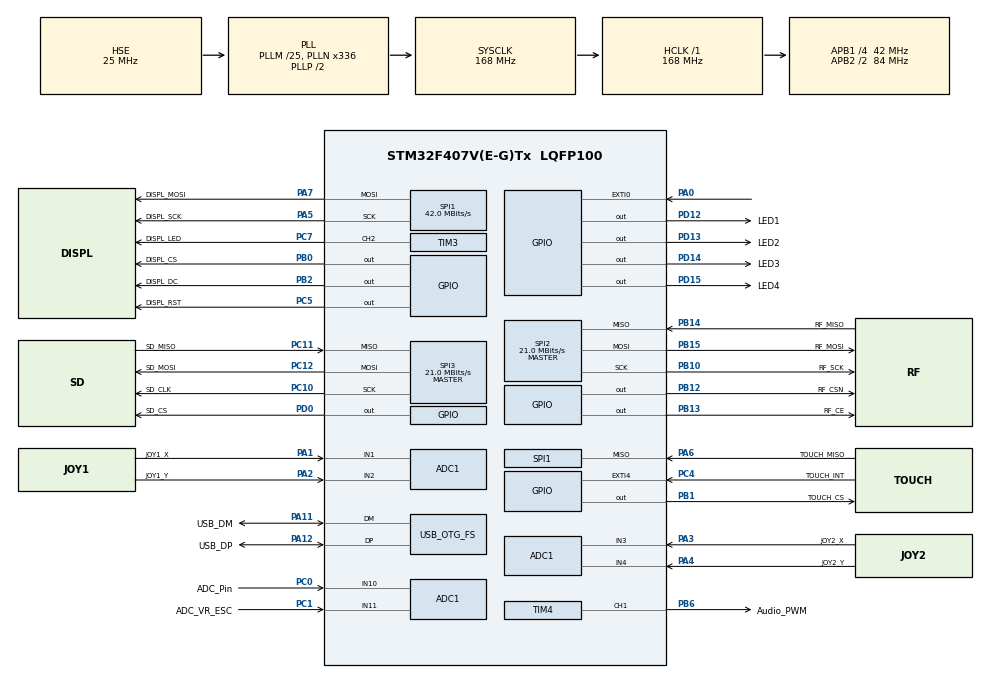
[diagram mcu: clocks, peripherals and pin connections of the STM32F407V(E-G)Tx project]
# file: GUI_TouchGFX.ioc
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ADC1.Channel-0\#ChannelRegularConversion=ADC_CHANNEL_1
ADC1.Channel-1\#ChannelRegularConversion=ADC_CHANNEL_2
ADC1.Channel-2\#ChannelRegularConversion=ADC_CHANNEL_3
ADC1.Channel-3\#ChannelRegularConversion=ADC_CHANNEL_4
ADC1.Channel-4\#ChannelRegularConversion=ADC_CHANNEL_10
ADC1.ClockPrescaler=ADC_CLOCK_SYNC_PCLK_DIV8
ADC1.ContinuousConvMode=DISABLE
ADC1.DiscontinuousConvMode=DISABLE
ADC1.EOCSelection=ADC_EOC_SINGLE_CONV
ADC1.NbrOfConversion=5
ADC1.NbrOfConversionFlag=1
ADC1.Rank-0\#ChannelRegularConversion=1
ADC1.Rank-1\#ChannelRegularConversion=2
ADC1.Rank-2\#ChannelRegularConversion=3
ADC1.Rank-3\#ChannelRegularConversion=4
ADC1.Rank-4\#ChannelRegularConversion=5
ADC1.SamplingTime-0\#ChannelRegularConversion=ADC_SAMPLETIME_144CYCLES
ADC1.SamplingTime-1\#ChannelRegularConversion=ADC_SAMPLETIME_144CYCLES
ADC1.SamplingTime-2\#ChannelRegularConversion=ADC_SAMPLETIME_144CYCLES
ADC1.SamplingTime-3\#ChannelRegularConversion=ADC_SAMPLETIME_144CYCLES
ADC1.SamplingTime-4\#ChannelRegularConversion=ADC_SAMPLETIME_144CYCLES
ADC1.ScanConvMode=ENABLE
ADC1.master=1
Dma.ADC1.1.Direction=DMA_PERIPH_TO_MEMORY
Dma.ADC1.1.FIFOMode=DMA_FIFOMODE_DISABLE
Dma.ADC1.1.Instance=DMA2_Stream0
Dma.ADC1.1.MemDataAlignment=DMA_MDATAALIGN_WORD
Dma.ADC1.1.MemInc=DMA_MINC_ENABLE
Dma.ADC1.1.Mode=DMA_CIRCULAR
Dma.ADC1.1.PeriphDataAlignment=DMA_PDATAALIGN_WORD
Dma.ADC1.1.PeriphInc=DMA_PINC_DISABLE
Dma.ADC1.1.Priority=DMA_PRIORITY_VERY_HIGH
Dma.Request0=SPI1_TX
Dma.Request1=ADC1
Dma.SPI1_TX.0.Direction=DMA_MEMORY_TO_PERIPH
Dma.SPI1_TX.0.FIFOMode=DMA_FIFOMODE_DISABLE
Dma.SPI1_TX.0.Instance=DMA2_Stream3
Dma.SPI1_TX.0.MemDataAlignment=DMA_MDATAALIGN_BYTE
Dma.SPI1_TX.0.MemInc=DMA_MINC_ENABLE
Dma.SPI1_TX.0.Mode=DMA_NORMAL
Dma.SPI1_TX.0.PeriphDataAlignment=DMA_PDATAALIGN_BYTE
Dma.SPI1_TX.0.PeriphInc=DMA_PINC_DISABLE
Dma.SPI1_TX.0.Priority=DMA_PRIORITY_VERY_HIGH
Mcu.Family=STM32F4
Mcu.Name=STM32F407V(E-G)Tx
Mcu.Package=LQFP100
NVIC.DMA2_Stream0_IRQn=true\:0\:0\:false\:false\:true\:false\:true\:true
NVIC.DMA2_Stream3_IRQn=true\:0\:0\:false\:false\:true\:false\:true\:true
NVIC.EXTI4_IRQn=true\:0\:0\:true\:false\:true\:true\:true\:true
NVIC.PriorityGroup=NVIC_PRIORITYGROUP_4
NVIC.SPI1_IRQn=true\:0\:0\:false\:false\:true\:true\:true\:true
PA0-WKUP.Signal=GPXTI0
PA1.GPIO_Label=JOY1_X
PA1.Signal=ADCx_IN1
PA11.GPIO_Label=USB_DM
PA11.Mode=Device_Only
PA11.Signal=USB_OTG_FS_DM
PA12.GPIO_Label=USB_DP
PA12.Mode=Device_Only
PA12.Signal=USB_OTG_FS_DP
PA13.Mode=Serial_Wire
PA13.Signal=SYS_JTMS-SWDIO
PA14.Mode=Serial_Wire
PA14.Signal=SYS_JTCK-SWCLK
PA2.GPIO_Label=JOY1_Y
PA2.Signal=ADCx_IN2
PA3.GPIO_Label=JOY2_X
PA3.Signal=ADCx_IN3
PA4.GPIO_Label=JOY2_Y
PA4.Signal=ADCx_IN4
PA5.GPIO_Label=DISPL_SCK
PA5.Mode=Full_Duplex_Master
PA5.Signal=SPI1_SCK
PA6.GPIO_Label=TOUCH_MISO
PA6.Mode=Full_Duplex_Master
PA6.Signal=SPI1_MISO
PA7.GPIO_Label=DISPL_MOSI
PA7.Mode=Full_Duplex_Master
PA7.Signal=SPI1_MOSI
PB0.GPIO_Label=DISPL_CS
PB0.GPIO_PuPd=GPIO_NOPULL
PB0.GPIO_Speed=GPIO_SPEED_FREQ_HIGH
PB0.PinState=GPIO_PIN_SET
PB0.Signal=GPIO_Output
PB1.GPIO_Label=TOUCH_CS
PB1.GPIO_Speed=GPIO_SPEED_FREQ_HIGH
PB1.PinState=GPIO_PIN_SET
PB1.Signal=GPIO_Output
PB10.GPIO_Label=RF_SCK
PB10.Mode=Full_Duplex_Master
PB10.Signal=SPI2_SCK
PB12.GPIO_Label=RF_CSN
PB12.Signal=GPIO_Output
PB13.GPIO_Label=RF_CE
PB13.Signal=GPIO_Output
PB14.GPIO_Label=RF_MISO
PB14.Mode=Full_Duplex_Master
PB14.Signal=SPI2_MISO
PB15.GPIO_Label=RF_MOSI
PB15.Mode=Full_Duplex_Master
PB15.Signal=SPI2_MOSI
PB2.GPIO_Label=DISPL_DC
PB2.GPIO_Speed=GPIO_SPEED_FREQ_HIGH
PB2.Signal=GPIO_Output
PB6.GPIO_Label=Audio_PWM
PB6.Signal=S_TIM4_CH1
PC0.GPIO_Label=ADC_Pin
PC0.Signal=ADCx_IN10
PC1.GPIO_Label=ADC_VR_ESC
PC1.Signal=ADCx_IN11
PC10.GPIO_Label=SD_CLK
PC10.Mode=Full_Duplex_Master
PC10.Signal=SPI3_SCK
PC11.GPIO_Label=SD_MISO
PC11.Mode=Full_Duplex_Master
PC11.Signal=SPI3_MISO
PC12.GPIO_Label=SD_MOSI
PC12.Mode=Full_Duplex_Master
PC12.Signal=SPI3_MOSI
PC4.GPIO_Label=TOUCH_INT
PC4.GPIO_ModeDefaultEXTI=GPIO_MODE_IT_FALLING
PC4.GPIO_PuPd=GPIO_PULLUP
PC4.Signal=GPXTI4
PC5.GPIO_Label=DISPL_RST
PC5.Signal=GPIO_Output
PC7.GPIO_Label=DISPL_LED
PC7.Signal=S_TIM3_CH2
PD0.GPIO_Label=SD_CS
PD0.Signal=GPIO_Output
PD12.GPIO_Label=LED1
PD12.Signal=GPIO_Output
PD13.GPIO_Label=LED2
PD13.Signal=GPIO_Output
PD14.GPIO_Label=LED3
PD14.Signal=GPIO_Output
PD15.GPIO_Label=LED4
PD15.Signal=GPIO_Output
PH0-OSC_IN.Mode=HSE-External-Oscillator
PH0-OSC_IN.Signal=RCC_OSC_IN
PH1-OSC_OUT.Mode=HSE-External-Oscillator
PH1-OSC_OUT.Signal=RCC_OSC_OUT
ProjectManager.HeapSize=0x200
ProjectManager.StackSize=0x400
ProjectManager.TargetToolchain=STM32CubeIDE
RCC.48MHZClocksFreq_Value=48000000
RCC.AHBFreq_Value=168000000
RCC.APB1CLKDivider=RCC_HCLK_DIV4
RCC.APB1Freq_Value=42000000
RCC.APB1TimFreq_Value=84000000
RCC.APB2CLKDivider=RCC_HCLK_DIV2
RCC.APB2Freq_Value=84000000
RCC.APB2TimFreq_Value=168000000
RCC.CortexFreq_Value=168000000
RCC.HCLKFreq_Value=168000000
RCC.HSE_VALUE=25000000
RCC.HSI_VALUE=16000000
RCC.LSE_VALUE=32768
RCC.PLLM=25
RCC.PLLN=336
RCC.PLLQ=7
RCC.SYSCLKFreq_VALUE=168000000
RCC.SYSCLKSource=RCC_SYSCLKSOURCE_PLLCLK
RCC.VCOOutputFreq_Value=336000000
SH.ADCx_IN1.0=ADC1_IN1,IN1
SH.ADCx_IN10.0=ADC1_IN10,IN10
SH.ADCx_IN11.0=ADC1_IN11,IN11
SH.ADCx_IN2.0=ADC1_IN2,IN2
SH.ADCx_IN3.0=ADC1_IN3,IN3
SH.ADCx_IN4.0=ADC1_IN4,IN4
SH.S_TIM3_CH2.0=TIM3_CH2,PWM Generation2 CH2
SH.S_TIM4_CH1.0=TIM4_CH1,PWM Generation1 CH1
SPI1.CalculateBaudRate=42.0 MBits/s
SPI1.Direction=SPI_DIRECTION_2LINES
SPI1.Mode=SPI_MODE_MASTER
SPI1.VirtualType=VM_MASTER
SPI2.CalculateBaudRate=21.0 MBits/s
SPI2.Direction=SPI_DIRECTION_2LINES
SPI2.Mode=SPI_MODE_MASTER
SPI2.VirtualType=VM_MASTER
SPI3.CalculateBaudRate=21.0 MBits/s
SPI3.Direction=SPI_DIRECTION_2LINES
SPI3.Mode=SPI_MODE_MASTER
SPI3.VirtualType=VM_MASTER
STMicroelectronics.X-CUBE-TOUCHGFX.4.23.2.ApplicationCcGraphicsJjApplication=TouchGFXOoGenerator
STMicroelectronics.X-CUBE-TOUCHGFX.4.23.2.tgfx_block_size=2800
STMicroelectronics.X-CUBE-TOUCHGFX.4.23.2.tgfx_buffering_strategy=Partial
STMicroelectronics.X-CUBE-TOUCHGFX.4.23.2.tgfx_custom_height=240
STMicroelectronics.X-CUBE-TOUCHGFX.4.23.2.tgfx_custom_width=320
STMicroelectronics.X-CUBE-TOUCHGFX.4.23.2_IsPackSelfContextualization=true
TIM2.Period=50
TIM2.Prescaler=42000
TIM3.Channel-PWM\ Generation2\ CH2=TIM_CHANNEL_2
TIM3.Period=100
TIM3.Prescaler=10000
TIM4.Channel-PWM\ Generation1\ CH1=TIM_CHANNEL_1
USB_OTG_FS.VirtualMode=Device_Only
VP_CRC_VS_CRC.Mode=CRC_Activate
VP_STMicroelectronics.X-CUBE-TOUCHGFX_VS_GraphicsJjApplication_4.23.2.Mode=GraphicsJjApplication
VP_TIM2_VS_ClockSourceINT.Mode=Internal
board=custom

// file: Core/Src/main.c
/* USER CODE BEGIN Header */
/**
  ******************************************************************************
  * @file           : main.c
  * @brief          : Main program body
  ******************************************************************************
  * @attention
  *
  * Copyright (c) 2024 STMicroelectronics.
  * All rights reserved.
  *
  * This software is licensed under terms that can be found in the LICENSE file
  * in the root directory of this software component.
  * If no LICENSE file comes with this software, it is provided AS-IS.
  *
  ******************************************************************************
  */
/* USER CODE END Header */
#include "main.h"
#include "app_touchgfx.h"

/* USER CODE BEGIN Includes */
#include <stdbool.h>
/* USER CODE END Includes */

ADC_HandleTypeDef hadc1;
DMA_HandleTypeDef hdma_adc1;

CRC_HandleTypeDef hcrc;

SPI_HandleTypeDef hspi1;
SPI_HandleTypeDef hspi2;
SPI_HandleTypeDef hspi3;
DMA_HandleTypeDef hdma_spi1_tx;

TIM_HandleTypeDef htim2;
TIM_HandleTypeDef htim3;
TIM_HandleTypeDef htim4;

PCD_HandleTypeDef hpcd_USB_OTG_FS;

/* USER CODE BEGIN PV */
uint8_t TxAddress[] = {0x17, 0x08, 0x04, 0x11, 0x02};
uint8_t TxData[3] ={0};
uint8_t a = 0;
uint32_t VR[5];
uint32_t value[5];
uint32_t check;
uint8_t Temp[2]= {0};
/* USER CODE END PV */

void SystemClock_Config(void);
static void MX_GPIO_Init(void);
static void MX_DMA_Init(void);
static void MX_SPI1_Init(void);
static void MX_CRC_Init(void);
static void MX_TIM3_Init(void);
static void MX_SPI2_Init(void);
static void MX_TIM2_Init(void);
static void MX_ADC1_Init(void);
static void MX_SPI3_Init(void);
static void MX_TIM4_Init(void);
static void MX_USB_OTG_FS_PCD_Init(void);

/* USER CODE BEGIN 0 */
long map(long x, long in_min, long in_max, long out_min, long out_max)
{
  return (x - in_min) * (out_max - out_min + 1) / (in_max - in_min + 1) + out_min;
}
/* USER CODE END 0 */

int main(void)
{

  /* MCU Configuration--------------------------------------------------------*/

  /* Reset of all peripherals, Initializes the Flash interface and the Systick. */
  HAL_Init();

  /* Configure the system clock */
  SystemClock_Config();

  /* Initialize all configured peripherals */
  MX_GPIO_Init();
  MX_DMA_Init();
  MX_SPI1_Init();
  MX_CRC_Init();
  MX_TIM3_Init();
  MX_SPI2_Init();
  MX_TIM2_Init();
  MX_ADC1_Init();
  MX_SPI3_Init();
  MX_TIM4_Init();
  MX_USB_OTG_FS_PCD_Init();
  MX_TouchGFX_Init();
  /* USER CODE BEGIN 2 */
//  Displ_Init(Displ_Orientat_90);		// initialize the display and set the initial display orientation (here is orientaton: 0°) - THIS FUNCTION MUST PRECEED ANY OTHER DISPLAY FUNCTION CALL.
//  touchgfxSignalVSync();		// asks TouchGFX to start initial display drawing
//  Displ_BackLight('I');
  /* USER CODE END 2 */

  /* Infinite loop */
  /* USER CODE BEGIN WHILE */
  while (1)
  {
	  HAL_ADC_Start_DMA(&hadc1, VR, 5);
	  HAL_Delay(10);
//	  for(uint8_t i = 0; i < 5; i++){
//		  value[i] = map(VR[i], 0 , 4095, 0 ,1024);
//	  }
//	  check = value[3];
//	  if(check > 512){
//		HAL_GPIO_WritePin(GPIOD, GPIO_PIN_12, 1);
//	  }
//	  else HAL_GPIO_WritePin(GPIOD, GPIO_PIN_12, 0);
//	  IntToStr6(Temp[0],TxData);
//	  if (Touch_GotATouch(0))
//	  	touchgfxSignalVSync();		// asks TouchGFX to handle touch and redraw screen
    /* USER CODE END WHILE */

  MX_TouchGFX_Process();
  }
}

void SystemClock_Config(void)
{
  RCC_OscInitTypeDef RCC_OscInitStruct = {0};
  RCC_ClkInitTypeDef RCC_ClkInitStruct = {0};

  /** Configure the main internal regulator output voltage
  */
  __HAL_RCC_PWR_CLK_ENABLE();
  __HAL_PWR_VOLTAGESCALING_CONFIG(PWR_REGULATOR_VOLTAGE_SCALE1);

  /** Initializes the RCC Oscillators according to the specified parameters
  * in the RCC_OscInitTypeDef structure.
  */
  RCC_OscInitStruct.OscillatorType = RCC_OSCILLATORTYPE_HSE;
  RCC_OscInitStruct.HSEState = RCC_HSE_ON;
  RCC_OscInitStruct.PLL.PLLState = RCC_PLL_ON;
  RCC_OscInitStruct.PLL.PLLSource = RCC_PLLSOURCE_HSE;
  RCC_OscInitStruct.PLL.PLLM = 25;
  RCC_OscInitStruct.PLL.PLLN = 336;
  RCC_OscInitStruct.PLL.PLLP = RCC_PLLP_DIV2;
  RCC_OscInitStruct.PLL.PLLQ = 7;
  if (HAL_RCC_OscConfig(&RCC_OscInitStruct) != HAL_OK)
  {
    Error_Handler();
  }

  /** Initializes the CPU, AHB and APB buses clocks
  */
  RCC_ClkInitStruct.ClockType = RCC_CLOCKTYPE_HCLK|RCC_CLOCKTYPE_SYSCLK
                              |RCC_CLOCKTYPE_PCLK1|RCC_CLOCKTYPE_PCLK2;
  RCC_ClkInitStruct.SYSCLKSource = RCC_SYSCLKSOURCE_PLLCLK;
  RCC_ClkInitStruct.AHBCLKDivider = RCC_SYSCLK_DIV1;
  RCC_ClkInitStruct.APB1CLKDivider = RCC_HCLK_DIV4;
  RCC_ClkInitStruct.APB2CLKDivider = RCC_HCLK_DIV2;

  if (HAL_RCC_ClockConfig(&RCC_ClkInitStruct, FLASH_LATENCY_5) != HAL_OK)
  {
    Error_Handler();
  }
}

static void MX_ADC1_Init(void)
{

  ADC_ChannelConfTypeDef sConfig = {0};

  /** Configure the global features of the ADC (Clock, Resolution, Data Alignment and number of conversion)
  */
  hadc1.Instance = ADC1;
  hadc1.Init.ClockPrescaler = ADC_CLOCK_SYNC_PCLK_DIV8;
  hadc1.Init.Resolution = ADC_RESOLUTION_12B;
  hadc1.Init.ScanConvMode = ENABLE;
  hadc1.Init.ContinuousConvMode = DISABLE;
  hadc1.Init.DiscontinuousConvMode = DISABLE;
  hadc1.Init.ExternalTrigConvEdge = ADC_EXTERNALTRIGCONVEDGE_NONE;
  hadc1.Init.ExternalTrigConv = ADC_SOFTWARE_START;
  hadc1.Init.DataAlign = ADC_DATAALIGN_RIGHT;
  hadc1.Init.NbrOfConversion = 5;
  hadc1.Init.DMAContinuousRequests = DISABLE;
  hadc1.Init.EOCSelection = ADC_EOC_SINGLE_CONV;
  if (HAL_ADC_Init(&hadc1) != HAL_OK)
  {
    Error_Handler();
  }

  /** Configure for the selected ADC regular channel its corresponding rank in the sequencer and its sample time.
  */
  sConfig.Channel = ADC_CHANNEL_1;
  sConfig.Rank = 1;
  sConfig.SamplingTime = ADC_SAMPLETIME_144CYCLES;
  if (HAL_ADC_ConfigChannel(&hadc1, &sConfig) != HAL_OK)
  {
    Error_Handler();
  }

  /** Configure for the selected ADC regular channel its corresponding rank in the sequencer and its sample time.
  */
  sConfig.Channel = ADC_CHANNEL_2;
  sConfig.Rank = 2;
  if (HAL_ADC_ConfigChannel(&hadc1, &sConfig) != HAL_OK)
  {
    Error_Handler();
  }

  /** Configure for the selected ADC regular channel its corresponding rank in the sequencer and its sample time.
  */
  sConfig.Channel = ADC_CHANNEL_3;
  sConfig.Rank = 3;
  if (HAL_ADC_ConfigChannel(&hadc1, &sConfig) != HAL_OK)
  {
    Error_Handler();
  }

  /** Configure for the selected ADC regular channel its corresponding rank in the sequencer and its sample time.
  */
  sConfig.Channel = ADC_CHANNEL_4;
  sConfig.Rank = 4;
  if (HAL_ADC_ConfigChannel(&hadc1, &sConfig) != HAL_OK)
  {
    Error_Handler();
  }

  /** Configure for the selected ADC regular channel its corresponding rank in the sequencer and its sample time.
  */
  sConfig.Channel = ADC_CHANNEL_10;
  sConfig.Rank = 5;
  if (HAL_ADC_ConfigChannel(&hadc1, &sConfig) != HAL_OK)
  {
    Error_Handler();
  }

}

static void MX_CRC_Init(void)
{

  hcrc.Instance = CRC;
  if (HAL_CRC_Init(&hcrc) != HAL_OK)
  {
    Error_Handler();
  }

}

static void MX_SPI1_Init(void)
{

  /* SPI1 parameter configuration*/
  hspi1.Instance = SPI1;
  hspi1.Init.Mode = SPI_MODE_MASTER;
  hspi1.Init.Direction = SPI_DIRECTION_2LINES;
  hspi1.Init.DataSize = SPI_DATASIZE_8BIT;
  hspi1.Init.CLKPolarity = SPI_POLARITY_LOW;
  hspi1.Init.CLKPhase = SPI_PHASE_1EDGE;
  hspi1.Init.NSS = SPI_NSS_SOFT;
  hspi1.Init.BaudRatePrescaler = SPI_BAUDRATEPRESCALER_2;
  hspi1.Init.FirstBit = SPI_FIRSTBIT_MSB;
  hspi1.Init.TIMode = SPI_TIMODE_DISABLE;
  hspi1.Init.CRCCalculation = SPI_CRCCALCULATION_DISABLE;
  hspi1.Init.CRCPolynomial = 10;
  if (HAL_SPI_Init(&hspi1) != HAL_OK)
  {
    Error_Handler();
  }

}

static void MX_SPI2_Init(void)
{

  /* SPI2 parameter configuration*/
  hspi2.Instance = SPI2;
  hspi2.Init.Mode = SPI_MODE_MASTER;
  hspi2.Init.Direction = SPI_DIRECTION_2LINES;
  hspi2.Init.DataSize = SPI_DATASIZE_8BIT;
  hspi2.Init.CLKPolarity = SPI_POLARITY_LOW;
  hspi2.Init.CLKPhase = SPI_PHASE_1EDGE;
  hspi2.Init.NSS = SPI_NSS_SOFT;
  hspi2.Init.BaudRatePrescaler = SPI_BAUDRATEPRESCALER_2;
  hspi2.Init.FirstBit = SPI_FIRSTBIT_MSB;
  hspi2.Init.TIMode = SPI_TIMODE_DISABLE;
  hspi2.Init.CRCCalculation = SPI_CRCCALCULATION_DISABLE;
  hspi2.Init.CRCPolynomial = 10;
  if (HAL_SPI_Init(&hspi2) != HAL_OK)
  {
    Error_Handler();
  }

}

static void MX_SPI3_Init(void)
{

  /* SPI3 parameter configuration*/
  hspi3.Instance = SPI3;
  hspi3.Init.Mode = SPI_MODE_MASTER;
  hspi3.Init.Direction = SPI_DIRECTION_2LINES;
  hspi3.Init.DataSize = SPI_DATASIZE_8BIT;
  hspi3.Init.CLKPolarity = SPI_POLARITY_LOW;
  hspi3.Init.CLKPhase = SPI_PHASE_1EDGE;
  hspi3.Init.NSS = SPI_NSS_SOFT;
  hspi3.Init.BaudRatePrescaler = SPI_BAUDRATEPRESCALER_2;
  hspi3.Init.FirstBit = SPI_FIRSTBIT_MSB;
  hspi3.Init.TIMode = SPI_TIMODE_DISABLE;
  hspi3.Init.CRCCalculation = SPI_CRCCALCULATION_DISABLE;
  hspi3.Init.CRCPolynomial = 10;
  if (HAL_SPI_Init(&hspi3) != HAL_OK)
  {
    Error_Handler();
  }

}

static void MX_TIM2_Init(void)
{

  TIM_ClockConfigTypeDef sClockSourceConfig = {0};
  TIM_MasterConfigTypeDef sMasterConfig = {0};

  htim2.Instance = TIM2;
  htim2.Init.Prescaler = 42000;
  htim2.Init.CounterMode = TIM_COUNTERMODE_UP;
  htim2.Init.Period = 50;
  htim2.Init.ClockDivision = TIM_CLOCKDIVISION_DIV1;
  htim2.Init.AutoReloadPreload = TIM_AUTORELOAD_PRELOAD_DISABLE;
  if (HAL_TIM_Base_Init(&htim2) != HAL_OK)
  {
    Error_Handler();
  }
  sClockSourceConfig.ClockSource = TIM_CLOCKSOURCE_INTERNAL;
  if (HAL_TIM_ConfigClockSource(&htim2, &sClockSourceConfig) != HAL_OK)
  {
    Error_Handler();
  }
  sMasterConfig.MasterOutputTrigger = TIM_TRGO_RESET;
  sMasterConfig.MasterSlaveMode = TIM_MASTERSLAVEMODE_DISABLE;
  if (HAL_TIMEx_MasterConfigSynchronization(&htim2, &sMasterConfig) != HAL_OK)
  {
    Error_Handler();
  }

}

static void MX_TIM3_Init(void)
{

  TIM_MasterConfigTypeDef sMasterConfig = {0};
  TIM_OC_InitTypeDef sConfigOC = {0};

  htim3.Instance = TIM3;
  htim3.Init.Prescaler = 10000;
  htim3.Init.CounterMode = TIM_COUNTERMODE_UP;
  htim3.Init.Period = 100;
  htim3.Init.ClockDivision = TIM_CLOCKDIVISION_DIV1;
  htim3.Init.AutoReloadPreload = TIM_AUTORELOAD_PRELOAD_DISABLE;
  if (HAL_TIM_PWM_Init(&htim3) != HAL_OK)
  {
    Error_Handler();
  }
  sMasterConfig.MasterOutputTrigger = TIM_TRGO_RESET;
  sMasterConfig.MasterSlaveMode = TIM_MASTERSLAVEMODE_DISABLE;
  if (HAL_TIMEx_MasterConfigSynchronization(&htim3, &sMasterConfig) != HAL_OK)
  {
    Error_Handler();
  }
  sConfigOC.OCMode = TIM_OCMODE_PWM1;
  sConfigOC.Pulse = 0;
  sConfigOC.OCPolarity = TIM_OCPOLARITY_HIGH;
  sConfigOC.OCFastMode = TIM_OCFAST_DISABLE;
  if (HAL_TIM_PWM_ConfigChannel(&htim3, &sConfigOC, TIM_CHANNEL_2) != HAL_OK)
  {
    Error_Handler();
  }
  HAL_TIM_MspPostInit(&htim3);

}

static void MX_TIM4_Init(void)
{

  TIM_MasterConfigTypeDef sMasterConfig = {0};
  TIM_OC_InitTypeDef sConfigOC = {0};

  htim4.Instance = TIM4;
  htim4.Init.Prescaler = 0;
  htim4.Init.CounterMode = TIM_COUNTERMODE_UP;
  htim4.Init.Period = 65535;
  htim4.Init.ClockDivision = TIM_CLOCKDIVISION_DIV1;
  htim4.Init.AutoReloadPreload = TIM_AUTORELOAD_PRELOAD_DISABLE;
  if (HAL_TIM_PWM_Init(&htim4) != HAL_OK)
  {
    Error_Handler();
  }
  sMasterConfig.MasterOutputTrigger = TIM_TRGO_RESET;
  sMasterConfig.MasterSlaveMode = TIM_MASTERSLAVEMODE_DISABLE;
  if (HAL_TIMEx_MasterConfigSynchronization(&htim4, &sMasterConfig) != HAL_OK)
  {
    Error_Handler();
  }
  sConfigOC.OCMode = TIM_OCMODE_PWM1;
  sConfigOC.Pulse = 0;
  sConfigOC.OCPolarity = TIM_OCPOLARITY_HIGH;
  sConfigOC.OCFastMode = TIM_OCFAST_DISABLE;
  if (HAL_TIM_PWM_ConfigChannel(&htim4, &sConfigOC, TIM_CHANNEL_1) != HAL_OK)
  {
    Error_Handler();
  }
  HAL_TIM_MspPostInit(&htim4);

}

static void MX_USB_OTG_FS_PCD_Init(void)
{

  hpcd_USB_OTG_FS.Instance = USB_OTG_FS;
  hpcd_USB_OTG_FS.Init.dev_endpoints = 4;
  hpcd_USB_OTG_FS.Init.speed = PCD_SPEED_FULL;
  hpcd_USB_OTG_FS.Init.dma_enable = DISABLE;
  hpcd_USB_OTG_FS.Init.phy_itface = PCD_PHY_EMBEDDED;
  hpcd_USB_OTG_FS.Init.Sof_enable = DISABLE;
  hpcd_USB_OTG_FS.Init.low_power_enable = DISABLE;
  hpcd_USB_OTG_FS.Init.lpm_enable = DISABLE;
  hpcd_USB_OTG_FS.Init.vbus_sensing_enable = DISABLE;
  hpcd_USB_OTG_FS.Init.use_dedicated_ep1 = DISABLE;
  if (HAL_PCD_Init(&hpcd_USB_OTG_FS) != HAL_OK)
  {
    Error_Handler();
  }

}

static void MX_DMA_Init(void)
{

  /* DMA controller clock enable */
  __HAL_RCC_DMA2_CLK_ENABLE();

  /* DMA interrupt init */
  /* DMA2_Stream0_IRQn interrupt configuration */
  HAL_NVIC_SetPriority(DMA2_Stream0_IRQn, 0, 0);
  HAL_NVIC_EnableIRQ(DMA2_Stream0_IRQn);
  /* DMA2_Stream3_IRQn interrupt configuration */
  HAL_NVIC_SetPriority(DMA2_Stream3_IRQn, 0, 0);
  HAL_NVIC_EnableIRQ(DMA2_Stream3_IRQn);

}

static void MX_GPIO_Init(void)
{
  GPIO_InitTypeDef GPIO_InitStruct = {0};

  /* GPIO Ports Clock Enable */
  __HAL_RCC_GPIOH_CLK_ENABLE();
  __HAL_RCC_GPIOC_CLK_ENABLE();
  __HAL_RCC_GPIOA_CLK_ENABLE();
  __HAL_RCC_GPIOB_CLK_ENABLE();
  __HAL_RCC_GPIOD_CLK_ENABLE();

  /*Configure GPIO pin Output Level */
  HAL_GPIO_WritePin(DISPL_RST_GPIO_Port, DISPL_RST_Pin, GPIO_PIN_RESET);

  /*Configure GPIO pin Output Level */
  HAL_GPIO_WritePin(GPIOB, DISPL_CS_Pin|TOUCH_CS_Pin, GPIO_PIN_SET);

  /*Configure GPIO pin Output Level */
  HAL_GPIO_WritePin(GPIOB, DISPL_DC_Pin|RF_CSN_Pin|RF_CE_Pin, GPIO_PIN_RESET);

  /*Configure GPIO pin Output Level */
  HAL_GPIO_WritePin(GPIOD, LED1_Pin|LED2_Pin|LED3_Pin|LED4_Pin
                          |SD_CS_Pin, GPIO_PIN_RESET);

  /*Configure GPIO pin : PA0 */
  GPIO_InitStruct.Pin = GPIO_PIN_0;
  GPIO_InitStruct.Mode = GPIO_MODE_IT_RISING;
  GPIO_InitStruct.Pull = GPIO_NOPULL;
  HAL_GPIO_Init(GPIOA, &GPIO_InitStruct);

  /*Configure GPIO pin : TOUCH_INT_Pin */
  GPIO_InitStruct.Pin = TOUCH_INT_Pin;
  GPIO_InitStruct.Mode = GPIO_MODE_IT_FALLING;
  GPIO_InitStruct.Pull = GPIO_PULLUP;
  HAL_GPIO_Init(TOUCH_INT_GPIO_Port, &GPIO_InitStruct);

  /*Configure GPIO pin : DISPL_RST_Pin */
  GPIO_InitStruct.Pin = DISPL_RST_Pin;
  GPIO_InitStruct.Mode = GPIO_MODE_OUTPUT_PP;
  GPIO_InitStruct.Pull = GPIO_NOPULL;
  GPIO_InitStruct.Speed = GPIO_SPEED_FREQ_LOW;
  HAL_GPIO_Init(DISPL_RST_GPIO_Port, &GPIO_InitStruct);

  /*Configure GPIO pins : DISPL_CS_Pin TOUCH_CS_Pin DISPL_DC_Pin */
  GPIO_InitStruct.Pin = DISPL_CS_Pin|TOUCH_CS_Pin|DISPL_DC_Pin;
  GPIO_InitStruct.Mode = GPIO_MODE_OUTPUT_PP;
  GPIO_InitStruct.Pull = GPIO_NOPULL;
  GPIO_InitStruct.Speed = GPIO_SPEED_FREQ_HIGH;
  HAL_GPIO_Init(GPIOB, &GPIO_InitStruct);

  /*Configure GPIO pins : RF_CSN_Pin RF_CE_Pin */
  GPIO_InitStruct.Pin = RF_CSN_Pin|RF_CE_Pin;
  GPIO_InitStruct.Mode = GPIO_MODE_OUTPUT_PP;
  GPIO_InitStruct.Pull = GPIO_NOPULL;
  GPIO_InitStruct.Speed = GPIO_SPEED_FREQ_LOW;
  HAL_GPIO_Init(GPIOB, &GPIO_InitStruct);

  /*Configure GPIO pins : LED1_Pin LED2_Pin LED3_Pin LED4_Pin
                           SD_CS_Pin */
  GPIO_InitStruct.Pin = LED1_Pin|LED2_Pin|LED3_Pin|LED4_Pin
                          |SD_CS_Pin;
  GPIO_InitStruct.Mode = GPIO_MODE_OUTPUT_PP;
  GPIO_InitStruct.Pull = GPIO_NOPULL;
  GPIO_InitStruct.Speed = GPIO_SPEED_FREQ_LOW;
  HAL_GPIO_Init(GPIOD, &GPIO_InitStruct);

  /* EXTI interrupt init*/
  HAL_NVIC_SetPriority(EXTI4_IRQn, 0, 0);
  HAL_NVIC_EnableIRQ(EXTI4_IRQn);

}

void Error_Handler(void)
{
  __disable_irq();
  while (1)
  {
  }
}
